AUTOSAR XML (schema 00046)
package /ComponentTypes
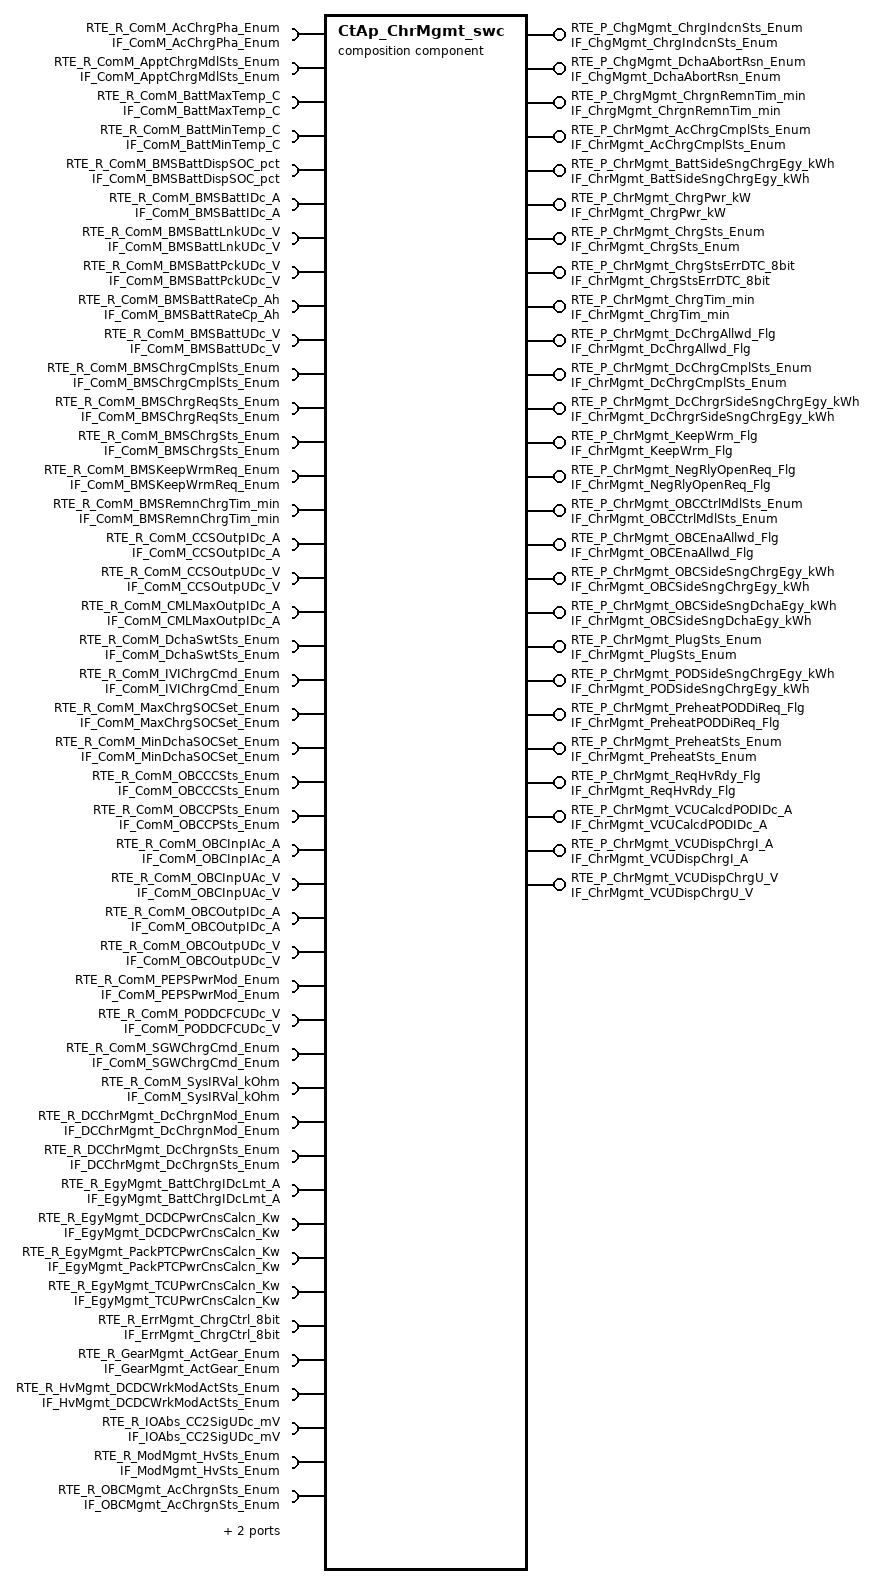
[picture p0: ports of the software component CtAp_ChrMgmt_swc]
  composition sw component type CtAp_ChrMgmt_swc
    26 x provide port:
      RTE_P_ChgMgmt_ChrgIndcnSts_Enum: nonqueued-sender-com-spec{data-element=tec_ChgMgmt_ChrgIndcnSts_Enum, init-value=0}, provided-interface=IF_ChgMgmt_ChrgIndcnSts_Enum
      RTE_P_ChgMgmt_DchaAbortRsn_Enum: nonqueued-sender-com-spec{data-element=tec_ChgMgmt_DchaAbortRsn_Enum, init-value=0}, provided-interface=IF_ChgMgmt_DchaAbortRsn_Enum
      RTE_P_ChrgMgmt_ChrgnRemnTim_min: nonqueued-sender-com-spec{data-element=tec_ChrgMgmt_ChrgnRemnTim_min, init-value=0}, provided-interface=IF_ChrgMgmt_ChrgnRemnTim_min
      RTE_P_ChrMgmt_AcChrgCmplSts_Enum: nonqueued-sender-com-spec{data-element=tec_ChrMgmt_AcChrgCmplSts_Enum, init-value=0}, provided-interface=IF_ChrMgmt_AcChrgCmplSts_Enum
      RTE_P_ChrMgmt_BattSideSngChrgEgy_kWh: nonqueued-sender-com-spec{data-element=tec_ChrMgmt_BattSideSngChrgEgy_kWh, init-value=0}, provided-interface=IF_ChrMgmt_BattSideSngChrgEgy_kWh
      RTE_P_ChrMgmt_ChrgPwr_kW: nonqueued-sender-com-spec{data-element=tec_ChrMgmt_ChrgPwr_kW, init-value=0}, provided-interface=IF_ChrMgmt_ChrgPwr_kW
      RTE_P_ChrMgmt_ChrgSts_Enum: nonqueued-sender-com-spec{data-element=tec_ChrMgmt_ChrgSts_Enum, init-value=0}, provided-interface=IF_ChrMgmt_ChrgSts_Enum
      RTE_P_ChrMgmt_ChrgStsErrDTC_8bit: nonqueued-sender-com-spec{data-element=tec_ChrMgmt_ChrgStsErrDTC_8bit, init-value=0}, provided-interface=IF_ChrMgmt_ChrgStsErrDTC_8bit
      RTE_P_ChrMgmt_ChrgTim_min: nonqueued-sender-com-spec{data-element=tec_ChrMgmt_ChrgTim_min, init-value=0}, provided-interface=IF_ChrMgmt_ChrgTim_min
      RTE_P_ChrMgmt_DcChrgAllwd_Flg: nonqueued-sender-com-spec{data-element=tec_ChrMgmt_DcChrgAllwd_Flg, init-value=0}, provided-interface=IF_ChrMgmt_DcChrgAllwd_Flg
      RTE_P_ChrMgmt_DcChrgCmplSts_Enum: nonqueued-sender-com-spec{data-element=tec_ChrMgmt_DcChrgCmplSts_Enum, init-value=0}, provided-interface=IF_ChrMgmt_DcChrgCmplSts_Enum
      RTE_P_ChrMgmt_DcChrgrSideSngChrgEgy_kWh: nonqueued-sender-com-spec{data-element=tec_ChrMgmt_DcChrgrSideSngChrgEgy_kWh, init-value=0}, provided-interface=IF_ChrMgmt_DcChrgrSideSngChrgEgy_kWh
      RTE_P_ChrMgmt_KeepWrm_Flg: nonqueued-sender-com-spec{data-element=tec_ChrMgmt_KeepWrm_Flg, init-value=0}, provided-interface=IF_ChrMgmt_KeepWrm_Flg
      RTE_P_ChrMgmt_NegRlyOpenReq_Flg: nonqueued-sender-com-spec{data-element=tec_ChrMgmt_NegRlyOpenReq_Flg, init-value=0}, provided-interface=IF_ChrMgmt_NegRlyOpenReq_Flg
      RTE_P_ChrMgmt_OBCCtrlMdlSts_Enum: nonqueued-sender-com-spec{data-element=tec_ChrMgmt_OBCCtrlMdlSts_Enum, init-value=0}, provided-interface=IF_ChrMgmt_OBCCtrlMdlSts_Enum
      RTE_P_ChrMgmt_OBCEnaAllwd_Flg: nonqueued-sender-com-spec{data-element=tec_ChrMgmt_OBCEnaAllwd_Flg, init-value=0}, provided-interface=IF_ChrMgmt_OBCEnaAllwd_Flg
      RTE_P_ChrMgmt_OBCSideSngChrgEgy_kWh: nonqueued-sender-com-spec{data-element=tec_ChrMgmt_OBCSideSngChrgEgy_kWh, init-value=0}, provided-interface=IF_ChrMgmt_OBCSideSngChrgEgy_kWh
      RTE_P_ChrMgmt_OBCSideSngDchaEgy_kWh: nonqueued-sender-com-spec{data-element=tec_ChrMgmt_OBCSideSngDchaEgy_kWh, init-value=0}, provided-interface=IF_ChrMgmt_OBCSideSngDchaEgy_kWh
      RTE_P_ChrMgmt_PlugSts_Enum: nonqueued-sender-com-spec{data-element=tec_ChrMgmt_PlugSts_Enum, init-value=0}, provided-interface=IF_ChrMgmt_PlugSts_Enum
      RTE_P_ChrMgmt_PODSideSngChrgEgy_kWh: nonqueued-sender-com-spec{data-element=tec_ChrMgmt_PODSideSngChrgEgy_kWh, init-value=0}, provided-interface=IF_ChrMgmt_PODSideSngChrgEgy_kWh
      RTE_P_ChrMgmt_PreheatPODDiReq_Flg: nonqueued-sender-com-spec{data-element=tec_ChrMgmt_PreheatPODDiReq_Flg, init-value=0}, provided-interface=IF_ChrMgmt_PreheatPODDiReq_Flg
      RTE_P_ChrMgmt_PreheatSts_Enum: nonqueued-sender-com-spec{data-element=tec_ChrMgmt_PreheatSts_Enum, init-value=0}, provided-interface=IF_ChrMgmt_PreheatSts_Enum
      RTE_P_ChrMgmt_ReqHvRdy_Flg: nonqueued-sender-com-spec{data-element=tec_ChrMgmt_ReqHvRdy_Flg, init-value=0}, provided-interface=IF_ChrMgmt_ReqHvRdy_Flg
      RTE_P_ChrMgmt_VCUCalcdPODIDc_A: nonqueued-sender-com-spec{data-element=tec_ChrMgmt_VCUCalcdPODIDc_A, init-value=0}, provided-interface=IF_ChrMgmt_VCUCalcdPODIDc_A
      RTE_P_ChrMgmt_VCUDispChrgI_A: nonqueued-sender-com-spec{data-element=tec_ChrMgmt_VCUDispChrgI_A, init-value=0}, provided-interface=IF_ChrMgmt_VCUDispChrgI_A
      RTE_P_ChrMgmt_VCUDispChrgU_V: nonqueued-sender-com-spec{data-element=tec_ChrMgmt_VCUDispChrgU_V, init-value=0}, provided-interface=IF_ChrMgmt_VCUDispChrgU_V
    46 x require port:
      RTE_R_ComM_AcChrgPha_Enum: nonqueued-receiver-com-spec{data-element=tec_ComM_AcChrgPha_Enum, filter=data-filter-type=ALWAYS, init-value=0}, required-interface=IF_ComM_AcChrgPha_Enum
      RTE_R_ComM_ApptChrgMdlSts_Enum: nonqueued-receiver-com-spec{data-element=tec_ComM_ApptChrgMdlSts_Enum, filter=data-filter-type=ALWAYS, init-value=0}, required-interface=IF_ComM_ApptChrgMdlSts_Enum
      RTE_R_ComM_BattMaxTemp_C: nonqueued-receiver-com-spec{data-element=tec_ComM_BMSBattMaxTemp_C, filter=data-filter-type=ALWAYS, init-value=0}, required-interface=IF_ComM_BattMaxTemp_C
      RTE_R_ComM_BattMinTemp_C: nonqueued-receiver-com-spec{data-element=tec_ComM_BMSBattMinTemp_C, filter=data-filter-type=ALWAYS, init-value=0}, required-interface=IF_ComM_BattMinTemp_C
      RTE_R_ComM_BMSBattDispSOC_pct: nonqueued-receiver-com-spec{data-element=tec_ComM_BMSBattDispSOC_pct, filter=data-filter-type=ALWAYS, init-value=0}, required-interface=IF_ComM_BMSBattDispSOC_pct
      RTE_R_ComM_BMSBattIDc_A: nonqueued-receiver-com-spec{data-element=tec_ComM_BMSBattIDc_A, filter=data-filter-type=ALWAYS, init-value=0}, required-interface=IF_ComM_BMSBattIDc_A
      RTE_R_ComM_BMSBattLnkUDc_V: nonqueued-receiver-com-spec{data-element=tec_ComM_BMSBattLnkUDc_V, filter=data-filter-type=ALWAYS, init-value=0}, required-interface=IF_ComM_BMSBattLnkUDc_V
      RTE_R_ComM_BMSBattPckUDc_V: nonqueued-receiver-com-spec{data-element=tec_ComM_BMSBattPckUDc_V, filter=data-filter-type=ALWAYS, init-value=0}, required-interface=IF_ComM_BMSBattPckUDc_V
      RTE_R_ComM_BMSBattRateCp_Ah: nonqueued-receiver-com-spec{data-element=tec_ComM_BMSBattRateCp_Ah, filter=data-filter-type=ALWAYS, init-value=0}, required-interface=IF_ComM_BMSBattRateCp_Ah
      RTE_R_ComM_BMSBattUDc_V: nonqueued-receiver-com-spec{data-element=tec_ComM_BMSBattUDc_V, filter=data-filter-type=ALWAYS, init-value=0}, required-interface=IF_ComM_BMSBattUDc_V
      RTE_R_ComM_BMSChrgCmplSts_Enum: nonqueued-receiver-com-spec{data-element=tec_ComM_BMSChrgCmplSts_Enum, filter=data-filter-type=ALWAYS, init-value=0}, required-interface=IF_ComM_BMSChrgCmplSts_Enum
      RTE_R_ComM_BMSChrgReqSts_Enum: nonqueued-receiver-com-spec{data-element=tec_ComM_BMSChrgReqSts_Enum, filter=data-filter-type=ALWAYS, init-value=0}, required-interface=IF_ComM_BMSChrgReqSts_Enum
      RTE_R_ComM_BMSChrgSts_Enum: nonqueued-receiver-com-spec{data-element=tec_ComM_BMSChrgSts_Enum, filter=data-filter-type=ALWAYS, init-value=0}, required-interface=IF_ComM_BMSChrgSts_Enum
      RTE_R_ComM_BMSKeepWrmReq_Enum: nonqueued-receiver-com-spec{data-element=tec_ComM_BMSKeepWrmReq_Enum, filter=data-filter-type=ALWAYS, init-value=0}, required-interface=IF_ComM_BMSKeepWrmReq_Enum
      RTE_R_ComM_BMSRemnChrgTim_min: nonqueued-receiver-com-spec{data-element=tec_ComM_BMSRemnChrgTim_min, filter=data-filter-type=ALWAYS, init-value=0}, required-interface=IF_ComM_BMSRemnChrgTim_min
      RTE_R_ComM_CCSOutpIDc_A: nonqueued-receiver-com-spec{data-element=tec_ComM_CCSOutpIDc_A, filter=data-filter-type=ALWAYS, init-value=0}, required-interface=IF_ComM_CCSOutpIDc_A
      RTE_R_ComM_CCSOutpUDc_V: nonqueued-receiver-com-spec{data-element=tec_ComM_CCSOutpUDc_V, filter=data-filter-type=ALWAYS, init-value=0}, required-interface=IF_ComM_CCSOutpUDc_V
      RTE_R_ComM_CMLMaxOutpIDc_A: nonqueued-receiver-com-spec{data-element=tec_ComM_CMLMaxOutpIDc_A, filter=data-filter-type=ALWAYS, init-value=0}, required-interface=IF_ComM_CMLMaxOutpIDc_A
      RTE_R_ComM_DchaSwtSts_Enum: nonqueued-receiver-com-spec{data-element=tec_ComM_DchaSwtSts_Enum, filter=data-filter-type=ALWAYS, init-value=0}, required-interface=IF_ComM_DchaSwtSts_Enum
      RTE_R_ComM_IVIChrgCmd_Enum: nonqueued-receiver-com-spec{data-element=tec_ComM_IVIChrgCmd_Enum, filter=data-filter-type=ALWAYS, init-value=0}, required-interface=IF_ComM_IVIChrgCmd_Enum
      RTE_R_ComM_MaxChrgSOCSet_Enum: nonqueued-receiver-com-spec{data-element=tec_ComM_MaxChrgSOCSet_Enum, filter=data-filter-type=ALWAYS}, required-interface=IF_ComM_MaxChrgSOCSet_Enum
      RTE_R_ComM_MinDchaSOCSet_Enum: nonqueued-receiver-com-spec{data-element=tec_ComM_MinDchaSOCSet_Enum, filter=data-filter-type=ALWAYS, init-value=0}, required-interface=IF_ComM_MinDchaSOCSet_Enum
      RTE_R_ComM_OBCCCSts_Enum: nonqueued-receiver-com-spec{data-element=tec_ComM_OBCCCSts_Enum, filter=data-filter-type=ALWAYS, init-value=0}, required-interface=IF_ComM_OBCCCSts_Enum
      RTE_R_ComM_OBCCPSts_Enum: nonqueued-receiver-com-spec{data-element=tec_ComM_OBCCPSts_Enum, filter=data-filter-type=ALWAYS, init-value=0}, required-interface=IF_ComM_OBCCPSts_Enum
      RTE_R_ComM_OBCInpIAc_A: nonqueued-receiver-com-spec{data-element=tec_ComM_OBCInpIAc_A, filter=data-filter-type=ALWAYS, init-value=0}, required-interface=IF_ComM_OBCInpIAc_A
      RTE_R_ComM_OBCInpUAc_V: nonqueued-receiver-com-spec{data-element=tec_ComM_OBCInpUAc_V, filter=data-filter-type=ALWAYS, init-value=0}, required-interface=IF_ComM_OBCInpUAc_V
      RTE_R_ComM_OBCOutpIDc_A: nonqueued-receiver-com-spec{data-element=tec_ComM_OBCOutpIDc_A, filter=data-filter-type=ALWAYS, init-value=0}, required-interface=IF_ComM_OBCOutpIDc_A
      RTE_R_ComM_OBCOutpUDc_V: nonqueued-receiver-com-spec{data-element=tec_ComM_OBCOutpUDc_V, filter=data-filter-type=ALWAYS, init-value=0}, required-interface=IF_ComM_OBCOutpUDc_V
      RTE_R_ComM_PEPSPwrMod_Enum: nonqueued-receiver-com-spec{data-element=tec_ComM_PEPSPwrMod_Enum, filter=data-filter-type=ALWAYS, init-value=0}, required-interface=IF_ComM_PEPSPwrMod_Enum
      RTE_R_ComM_PODDCFCUDc_V: nonqueued-receiver-com-spec{data-element=tec_ComM_PODDCFCUDc_V, filter=data-filter-type=ALWAYS, init-value=0}, required-interface=IF_ComM_PODDCFCUDc_V
      RTE_R_ComM_SGWChrgCmd_Enum: nonqueued-receiver-com-spec{data-element=tec_ComM_SGWChrgCmd_Enum, filter=data-filter-type=ALWAYS, init-value=0}, required-interface=IF_ComM_SGWChrgCmd_Enum
      RTE_R_ComM_SysIRVal_kOhm: nonqueued-receiver-com-spec{data-element=tec_ComM_SysIRVal_kOhm, filter=data-filter-type=ALWAYS, init-value=0}, required-interface=IF_ComM_SysIRVal_kOhm
      RTE_R_DCChrMgmt_DcChrgnMod_Enum: nonqueued-receiver-com-spec{data-element=tec_DCChrMgmt_DcChrgnMod_Enum, filter=data-filter-type=ALWAYS, init-value=0}, required-interface=IF_DCChrMgmt_DcChrgnMod_Enum
      RTE_R_DCChrMgmt_DcChrgnSts_Enum: nonqueued-receiver-com-spec{data-element=tec_DCChrMgmt_DcChrgnSts_Enum, filter=data-filter-type=ALWAYS, init-value=0}, required-interface=IF_DCChrMgmt_DcChrgnSts_Enum
      RTE_R_EgyMgmt_BattChrgIDcLmt_A: nonqueued-receiver-com-spec{data-element=tec_EgyMgmt_BattChrgIDcLmt_A, filter=data-filter-type=ALWAYS, init-value=0}, required-interface=IF_EgyMgmt_BattChrgIDcLmt_A
      RTE_R_EgyMgmt_DCDCPwrCnsCalcn_Kw: nonqueued-receiver-com-spec{data-element=tec_EgyMgmt_DCDCPwrCnsCalcn_Kw, filter=data-filter-type=ALWAYS, init-value=0}, required-interface=IF_EgyMgmt_DCDCPwrCnsCalcn_Kw
      RTE_R_EgyMgmt_PackPTCPwrCnsCalcn_Kw: nonqueued-receiver-com-spec{data-element=tec_EgyMgmt_PackPTCPwrCnsCalcn_Kw, filter=data-filter-type=ALWAYS, init-value=0}, required-interface=IF_EgyMgmt_PackPTCPwrCnsCalcn_Kw
      RTE_R_EgyMgmt_TCUPwrCnsCalcn_Kw: nonqueued-receiver-com-spec{data-element=tec_EgyMgmt_TCUPwrCnsCalcn_Kw, filter=data-filter-type=ALWAYS, init-value=0}, required-interface=IF_EgyMgmt_TCUPwrCnsCalcn_Kw
      RTE_R_ErrMgmt_ChrgCtrl_8bit: nonqueued-receiver-com-spec{data-element=tec_ErrMgmt_ChrgCtrl_8bit, filter=data-filter-type=ALWAYS, init-value=0}, required-interface=IF_ErrMgmt_ChrgCtrl_8bit
      RTE_R_GearMgmt_ActGear_Enum: nonqueued-receiver-com-spec{data-element=tec_GearMgmt_ActGear_Enum, filter=data-filter-type=ALWAYS, init-value=0}, required-interface=IF_GearMgmt_ActGear_Enum
      RTE_R_HvMgmt_DCDCWrkModActSts_Enum: nonqueued-receiver-com-spec{data-element=tec_HvMgmt_DCDCWrkModActSts_Enum, filter=data-filter-type=ALWAYS, init-value=0}, required-interface=IF_HvMgmt_DCDCWrkModActSts_Enum
      RTE_R_IOAbs_CC2SigUDc_mV: nonqueued-receiver-com-spec{data-element=tec_IOAbs_CC2SigUDc_mV, filter=data-filter-type=ALWAYS, init-value=0}, required-interface=IF_IOAbs_CC2SigUDc_mV
      RTE_R_ModMgmt_HvSts_Enum: nonqueued-receiver-com-spec{data-element=tec_ModMgmt_HvSts_Enum, filter=data-filter-type=ALWAYS, init-value=0}, required-interface=IF_ModMgmt_HvSts_Enum
      RTE_R_OBCMgmt_AcChrgnSts_Enum: nonqueued-receiver-com-spec{data-element=tec_OBCMgmt_AcChrgnSts_Enum, filter=data-filter-type=ALWAYS, init-value=0}, required-interface=IF_OBCMgmt_AcChrgnSts_Enum
      RTE_R_OBCMgmt_OBCOutpCpbyIDc_A: nonqueued-receiver-com-spec{data-element=tec_OBCMgmt_OBCOutpCpbyIDc_A, filter=data-filter-type=ALWAYS, init-value=0}, required-interface=IF_OBCMgmt_OBCOutpCpbyIDc_A
      RTE_R_VehMot_VehSpd_kph: nonqueued-receiver-com-spec{data-element=tec_VehMot_VehSpd_kph, filter=data-filter-type=ALWAYS, init-value=0}, required-interface=IF_VehMot_VehSpd_kph
    4 x component:
      CtAp_ChrgEgyCal: type=CtAp_ChrgEgyCal
      CtAp_ChrgPreHeat: type=CtAp_ChrgPreHeat
      CtAp_ChrgSdl: type=CtAp_ChrgSdl
      CtAp_ChrgStat: type=CtAp_ChrgStat
    connect CtAp_ChrgEgyCal.RTE_P_ChrMgmt_VCUCalcdPODIDc_A -> CtAp_ChrgStat.RTE_R_ChrMgmt_VCUCalcdPODIDc_A
    connect CtAp_ChrgPreHeat.RTE_P_ChrMgmt_PreheatSts_Enum -> CtAp_ChrgStat.RTE_R_ChrMgmt_PreheatSts_Enum
    connect CtAp_ChrgStat.RTE_P_ChrMgmt_ChrgSts_Enum -> CtAp_ChrgEgyCal.RTE_R_ChrMgmt_ChrgSts_Enum
    connect CtAp_ChrgStat.RTE_P_ChrMgmt_ChrgSts_Enum -> CtAp_ChrgPreHeat.RTE_R_ChrMgmt_ChrgSts_Enum
    connect CtAp_ChrgStat.RTE_P_ChrMgmt_ChrgSts_Enum -> CtAp_ChrgSdl.RTE_R_ChrMgmt_ChrgSts_Enum
    delegate CtAp_ChrgStat.RTE_P_ChgMgmt_ChrgIndcnSts_Enum <-> outer port RTE_P_ChgMgmt_ChrgIndcnSts_Enum
    delegate CtAp_ChrgStat.RTE_P_ChgMgmt_DchaAbortRsn_Enum <-> outer port RTE_P_ChgMgmt_DchaAbortRsn_Enum
    delegate CtAp_ChrgSdl.RTE_P_ChrgMgmt_ChrgnRemnTim_min <-> outer port RTE_P_ChrgMgmt_ChrgnRemnTim_min
    delegate CtAp_ChrgStat.RTE_P_ChrMgmt_AcChrgCmplSts_Enum <-> outer port RTE_P_ChrMgmt_AcChrgCmplSts_Enum
    delegate CtAp_ChrgEgyCal.RTE_P_ChrMgmt_BattSideSngChrgEgy_kWh <-> outer port RTE_P_ChrMgmt_BattSideSngChrgEgy_kWh
    delegate CtAp_ChrgEgyCal.RTE_P_ChrMgmt_ChrgPwr_kW <-> outer port RTE_P_ChrMgmt_ChrgPwr_kW
    delegate CtAp_ChrgStat.RTE_P_ChrMgmt_ChrgSts_Enum <-> outer port RTE_P_ChrMgmt_ChrgSts_Enum
    delegate CtAp_ChrgStat.RTE_P_ChrMgmt_ChrgStsErrDTC_8bit <-> outer port RTE_P_ChrMgmt_ChrgStsErrDTC_8bit
    delegate CtAp_ChrgSdl.RTE_P_ChrMgmt_ChrgTim_min <-> outer port RTE_P_ChrMgmt_ChrgTim_min
    delegate CtAp_ChrgStat.RTE_P_ChrMgmt_DcChrgAllwd_Flg <-> outer port RTE_P_ChrMgmt_DcChrgAllwd_Flg
    delegate CtAp_ChrgStat.RTE_P_ChrMgmt_DcChrgCmplSts_Enum <-> outer port RTE_P_ChrMgmt_DcChrgCmplSts_Enum
    delegate CtAp_ChrgEgyCal.RTE_P_ChrMgmt_DcChrgrSideSngChrgEgy_kWh <-> outer port RTE_P_ChrMgmt_DcChrgrSideSngChrgEgy_kWh
    delegate CtAp_ChrgStat.RTE_P_ChrMgmt_KeepWrm_Flg <-> outer port RTE_P_ChrMgmt_KeepWrm_Flg
    delegate CtAp_ChrgPreHeat.RTE_P_ChrMgmt_NegRlyOpenReq_Flg <-> outer port RTE_P_ChrMgmt_NegRlyOpenReq_Flg
    delegate CtAp_ChrgStat.RTE_P_ChrMgmt_OBCCtrlMdlSts_Enum <-> outer port RTE_P_ChrMgmt_OBCCtrlMdlSts_Enum
    delegate CtAp_ChrgStat.RTE_P_ChrMgmt_OBCEnaAllwd_Flg <-> outer port RTE_P_ChrMgmt_OBCEnaAllwd_Flg
    delegate CtAp_ChrgEgyCal.RTE_P_ChrMgmt_OBCSideSngChrgEgy_kWh <-> outer port RTE_P_ChrMgmt_OBCSideSngChrgEgy_kWh
    delegate CtAp_ChrgEgyCal.RTE_P_ChrMgmt_OBCSideSngDchaEgy_kWh <-> outer port RTE_P_ChrMgmt_OBCSideSngDchaEgy_kWh
    delegate CtAp_ChrgStat.RTE_P_ChrMgmt_PlugSts_Enum <-> outer port RTE_P_ChrMgmt_PlugSts_Enum
    delegate CtAp_ChrgEgyCal.RTE_P_ChrMgmt_PODSideSngChrgEgy_kWh <-> outer port RTE_P_ChrMgmt_PODSideSngChrgEgy_kWh
    delegate CtAp_ChrgPreHeat.RTE_P_ChrMgmt_PreheatPODDiReq_Flg <-> outer port RTE_P_ChrMgmt_PreheatPODDiReq_Flg
    delegate CtAp_ChrgPreHeat.RTE_P_ChrMgmt_PreheatSts_Enum <-> outer port RTE_P_ChrMgmt_PreheatSts_Enum
    delegate CtAp_ChrgStat.RTE_P_ChrMgmt_ReqHvRdy_Flg <-> outer port RTE_P_ChrMgmt_ReqHvRdy_Flg
    delegate CtAp_ChrgEgyCal.RTE_P_ChrMgmt_VCUCalcdPODIDc_A <-> outer port RTE_P_ChrMgmt_VCUCalcdPODIDc_A
    delegate CtAp_ChrgEgyCal.RTE_P_ChrMgmt_VCUDispChrgI_A <-> outer port RTE_P_ChrMgmt_VCUDispChrgI_A
    delegate CtAp_ChrgEgyCal.RTE_P_ChrMgmt_VCUDispChrgU_V <-> outer port RTE_P_ChrMgmt_VCUDispChrgU_V
    delegate CtAp_ChrgEgyCal.RTE_R_ComM_AcChrgPha_Enum <-> outer port RTE_R_ComM_AcChrgPha_Enum
    delegate CtAp_ChrgStat.RTE_R_ComM_ApptChrgMdlSts_Enum <-> outer port RTE_R_ComM_ApptChrgMdlSts_Enum
    delegate CtAp_ChrgSdl.RTE_R_ComM_BattMaxTemp_C <-> outer port RTE_R_ComM_BattMaxTemp_C
    delegate CtAp_ChrgSdl.RTE_R_ComM_BattMinTemp_C <-> outer port RTE_R_ComM_BattMinTemp_C
    delegate CtAp_ChrgSdl.RTE_R_ComM_BMSBattDispSOC_pct <-> outer port RTE_R_ComM_BMSBattDispSOC_pct
    delegate CtAp_ChrgStat.RTE_R_ComM_BMSBattDispSOC_pct <-> outer port RTE_R_ComM_BMSBattDispSOC_pct
    delegate CtAp_ChrgEgyCal.RTE_R_ComM_BMSBattIDc_A <-> outer port RTE_R_ComM_BMSBattIDc_A
    delegate CtAp_ChrgPreHeat.RTE_R_ComM_BMSBattIDc_A <-> outer port RTE_R_ComM_BMSBattIDc_A
    delegate CtAp_ChrgEgyCal.RTE_R_ComM_BMSBattLnkUDc_V <-> outer port RTE_R_ComM_BMSBattLnkUDc_V
    delegate CtAp_ChrgPreHeat.RTE_R_ComM_BMSBattPckUDc_V <-> outer port RTE_R_ComM_BMSBattPckUDc_V
    delegate CtAp_ChrgSdl.RTE_R_ComM_BMSBattRateCp_Ah <-> outer port RTE_R_ComM_BMSBattRateCp_Ah
    delegate CtAp_ChrgEgyCal.RTE_R_ComM_BMSBattUDc_V <-> outer port RTE_R_ComM_BMSBattUDc_V
    delegate CtAp_ChrgStat.RTE_R_ComM_BMSChrgCmplSts_Enum <-> outer port RTE_R_ComM_BMSChrgCmplSts_Enum
    delegate CtAp_ChrgStat.RTE_R_ComM_BMSChrgReqSts_Enum <-> outer port RTE_R_ComM_BMSChrgReqSts_Enum
    delegate CtAp_ChrgPreHeat.RTE_R_ComM_BMSChrgSts_Enum <-> outer port RTE_R_ComM_BMSChrgSts_Enum
    delegate CtAp_ChrgStat.RTE_R_ComM_BMSChrgSts_Enum <-> outer port RTE_R_ComM_BMSChrgSts_Enum
    delegate CtAp_ChrgStat.RTE_R_ComM_BMSKeepWrmReq_Enum <-> outer port RTE_R_ComM_BMSKeepWrmReq_Enum
    delegate CtAp_ChrgSdl.RTE_R_ComM_BMSRemnChrgTim_min <-> outer port RTE_R_ComM_BMSRemnChrgTim_min
    delegate CtAp_ChrgEgyCal.RTE_R_ComM_CCSOutpIDc_A <-> outer port RTE_R_ComM_CCSOutpIDc_A
    delegate CtAp_ChrgEgyCal.RTE_R_ComM_CCSOutpUDc_V <-> outer port RTE_R_ComM_CCSOutpUDc_V
    delegate CtAp_ChrgSdl.RTE_R_ComM_CMLMaxOutpIDc_A <-> outer port RTE_R_ComM_CMLMaxOutpIDc_A
    delegate CtAp_ChrgStat.RTE_R_ComM_DchaSwtSts_Enum <-> outer port RTE_R_ComM_DchaSwtSts_Enum
    delegate CtAp_ChrgStat.RTE_R_ComM_IVIChrgCmd_Enum <-> outer port RTE_R_ComM_IVIChrgCmd_Enum
    delegate CtAp_ChrgStat.RTE_R_ComM_MaxChrgSOCSet_Enum <-> outer port RTE_R_ComM_MaxChrgSOCSet_Enum
    delegate CtAp_ChrgStat.RTE_R_ComM_MinDchaSOCSet_Enum <-> outer port RTE_R_ComM_MinDchaSOCSet_Enum
    delegate CtAp_ChrgStat.RTE_R_ComM_OBCCCSts_Enum <-> outer port RTE_R_ComM_OBCCCSts_Enum
    delegate CtAp_ChrgStat.RTE_R_ComM_OBCCPSts_Enum <-> outer port RTE_R_ComM_OBCCPSts_Enum
    delegate CtAp_ChrgEgyCal.RTE_R_ComM_OBCInpIAc_A <-> outer port RTE_R_ComM_OBCInpIAc_A
    delegate CtAp_ChrgEgyCal.RTE_R_ComM_OBCInpUAc_V <-> outer port RTE_R_ComM_OBCInpUAc_V
    delegate CtAp_ChrgEgyCal.RTE_R_ComM_OBCOutpIDc_A <-> outer port RTE_R_ComM_OBCOutpIDc_A
    delegate CtAp_ChrgStat.RTE_R_ComM_OBCOutpIDc_A <-> outer port RTE_R_ComM_OBCOutpIDc_A
    delegate CtAp_ChrgEgyCal.RTE_R_ComM_OBCOutpUDc_V <-> outer port RTE_R_ComM_OBCOutpUDc_V
    delegate CtAp_ChrgPreHeat.RTE_R_ComM_OBCOutpUDc_V <-> outer port RTE_R_ComM_OBCOutpUDc_V
    delegate CtAp_ChrgStat.RTE_R_ComM_PEPSPwrMod_Enum <-> outer port RTE_R_ComM_PEPSPwrMod_Enum
    delegate CtAp_ChrgEgyCal.RTE_R_ComM_PODDCFCUDc_V <-> outer port RTE_R_ComM_PODDCFCUDc_V
    delegate CtAp_ChrgPreHeat.RTE_R_ComM_PODDCFCUDc_V <-> outer port RTE_R_ComM_PODDCFCUDc_V
    delegate CtAp_ChrgStat.RTE_R_ComM_SGWChrgCmd_Enum <-> outer port RTE_R_ComM_SGWChrgCmd_Enum
    delegate CtAp_ChrgPreHeat.RTE_R_ComM_SysIRVal_kOhm <-> outer port RTE_R_ComM_SysIRVal_kOhm
    delegate CtAp_ChrgSdl.RTE_R_DCChrMgmt_DcChrgnMod_Enum <-> outer port RTE_R_DCChrMgmt_DcChrgnMod_Enum
    delegate CtAp_ChrgPreHeat.RTE_R_DCChrMgmt_DcChrgnSts_Enum <-> outer port RTE_R_DCChrMgmt_DcChrgnSts_Enum
    delegate CtAp_ChrgStat.RTE_R_DCChrMgmt_DcChrgnSts_Enum <-> outer port RTE_R_DCChrMgmt_DcChrgnSts_Enum
    delegate CtAp_ChrgSdl.RTE_R_EgyMgmt_BattChrgIDcLmt_A <-> outer port RTE_R_EgyMgmt_BattChrgIDcLmt_A
    delegate CtAp_ChrgEgyCal.RTE_R_EgyMgmt_DCDCPwrCnsCalcn_Kw <-> outer port RTE_R_EgyMgmt_DCDCPwrCnsCalcn_Kw
    delegate CtAp_ChrgEgyCal.RTE_R_EgyMgmt_PackPTCPwrCnsCalcn_Kw <-> outer port RTE_R_EgyMgmt_PackPTCPwrCnsCalcn_Kw
    delegate CtAp_ChrgEgyCal.RTE_R_EgyMgmt_TCUPwrCnsCalcn_Kw <-> outer port RTE_R_EgyMgmt_TCUPwrCnsCalcn_Kw
    delegate CtAp_ChrgStat.RTE_R_ErrMgmt_ChrgCtrl_8bit <-> outer port RTE_R_ErrMgmt_ChrgCtrl_8bit
    delegate CtAp_ChrgStat.RTE_R_GearMgmt_ActGear_Enum <-> outer port RTE_R_GearMgmt_ActGear_Enum
    delegate CtAp_ChrgPreHeat.RTE_R_HvMgmt_DCDCWrkModActSts_Enum <-> outer port RTE_R_HvMgmt_DCDCWrkModActSts_Enum
    delegate CtAp_ChrgStat.RTE_R_HvMgmt_DCDCWrkModActSts_Enum <-> outer port RTE_R_HvMgmt_DCDCWrkModActSts_Enum
    delegate CtAp_ChrgStat.RTE_R_IOAbs_CC2SigUDc_mV <-> outer port RTE_R_IOAbs_CC2SigUDc_mV
    delegate CtAp_ChrgPreHeat.RTE_R_ModMgmt_HvSts_Enum <-> outer port RTE_R_ModMgmt_HvSts_Enum
    delegate CtAp_ChrgStat.RTE_R_ModMgmt_HvSts_Enum <-> outer port RTE_R_ModMgmt_HvSts_Enum
    delegate CtAp_ChrgPreHeat.RTE_R_OBCMgmt_AcChrgnSts_Enum <-> outer port RTE_R_OBCMgmt_AcChrgnSts_Enum
    delegate CtAp_ChrgStat.RTE_R_OBCMgmt_AcChrgnSts_Enum <-> outer port RTE_R_OBCMgmt_AcChrgnSts_Enum
    delegate CtAp_ChrgSdl.RTE_R_OBCMgmt_OBCOutpCpbyIDc_A <-> outer port RTE_R_OBCMgmt_OBCOutpCpbyIDc_A
    delegate CtAp_ChrgStat.RTE_R_VehMot_VehSpd_kph <-> outer port RTE_R_VehMot_VehSpd_kph
